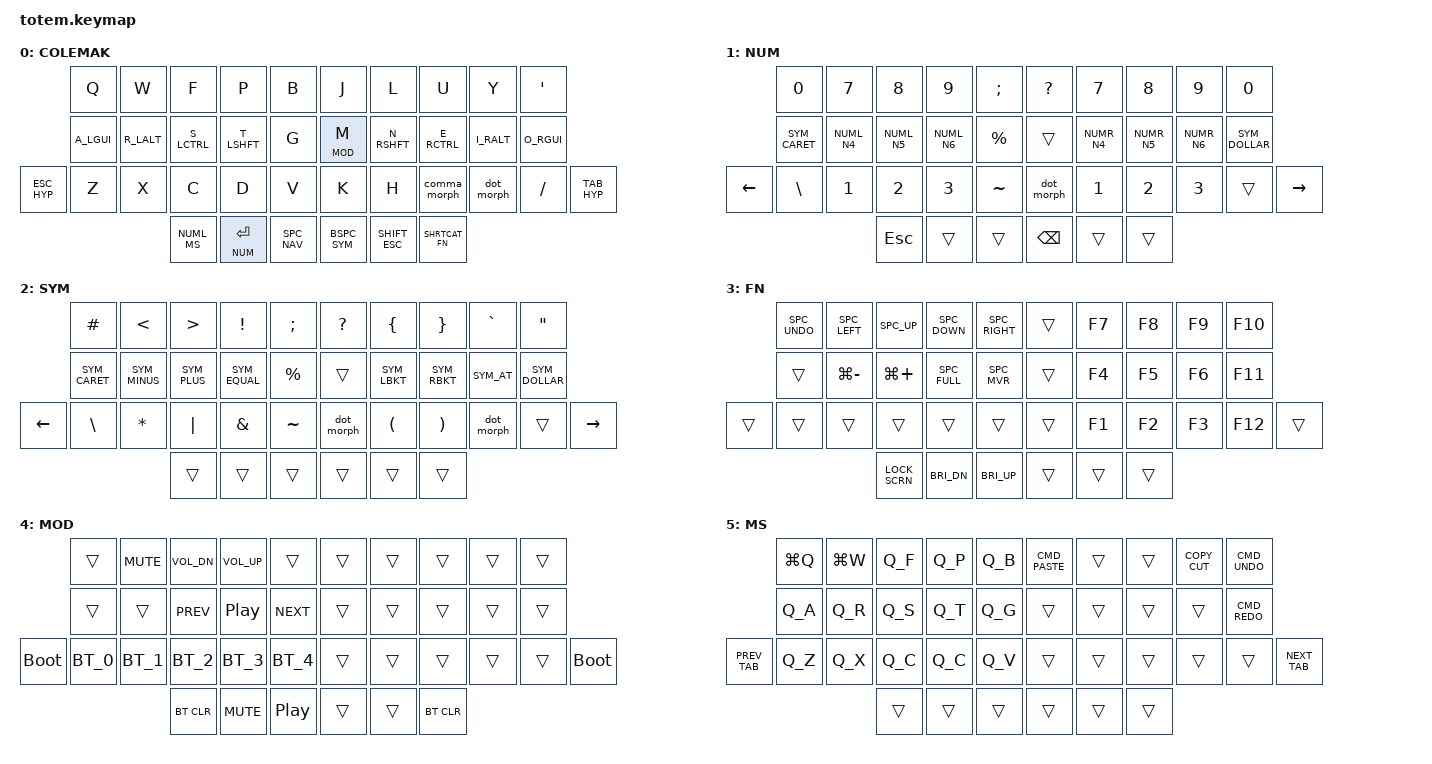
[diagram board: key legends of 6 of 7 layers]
//
//                                                        ▀▀▀▀▀     ▀▀▀▀▀          ▀▀█▀▀
//                                                        ▄▀▀▀▄  ▄  ▄▀▀▀▄  ▄  ▄▀▀▀▄  █  ▄▀▀▀▄
//                                                        █   █  █  █   █  █  █   █  █  █   █
//                                                         ▀▀▀   █   ▀▀▀   █   ▀▀▀   ▀   ▀▀▀
//                                                               █      ▄▄▄█▄▄▄    █   █
//                                                               ▀      █  █  █     █▄█
//                                                             ▀▀▀▀▀    █  █  █      ▀
//                                                                      ▀  ▀  ▀
//
// ▄▄▄▄▄▄▄▄▄▄▄▄▄▄▄▄▄▄▄▄▄▄▄▄▄▄▄▄▄▄▄▄▄▄▄▄▄▄▄▄▄▄▄▄▄▄▄▄▄▄▄▄▄▄▄▄▄▄▄▄▄▄▄▄▄▄▄▄▄▄▄▄▄▄▄▄▄▄▄▄▄▄▄▄▄▄▄▄▄▄▄▄▄▄▄▄▄▄▄▄▄▄▄▄▄▄▄▄▄▄▄▄▄▄▄▄▄▄▄▄▄▄▄▄▄▄▄▄▄▄▄▄▄▄▄▄▄▄▄▄▄▄▄▄▄▄▄▄▄


#include <behaviors.dtsi>
#include <behaviors/num_word.dtsi>
#include <dt-bindings/zmk/keys.h>
#include <dt-bindings/zmk/bt.h>
#include <dt-bindings/zmk/outputs.h>
#include "zmk-helpers/helper.h"

#include "totem_keypos.h"

#include "mouse.h"

#define ___ &trans

#define DEF 0 // Default colemak layer
#define NUM 1
#define SYM 2
#define FN 3
#define MOD 4
#define MS 5
#define NAV 6

/* Global settings */
#include "general.h"

/* Home row mods */
#include "homerow_mods.h"

/* Macros and shortcuts */
#include "custom_behaviors.h"

#include "combos.h"

/ {
        keymap {
                compatible = "zmk,keymap";
// ▄▄▄▄▄▄▄▄▄▄▄▄▄▄▄▄▄▄▄▄▄▄▄▄▄▄▄▄▄▄▄▄▄▄▄▄▄▄▄▄▄▄▄▄▄▄▄▄▄▄▄▄▄▄▄▄▄▄▄▄▄▄▄▄▄▄▄▄▄▄▄▄▄▄▄▄▄▄▄▄▄▄▄▄▄▄▄▄▄▄▄▄▄▄▄▄▄▄▄▄▄▄▄▄▄▄▄▄▄▄▄▄▄▄▄▄▄▄▄▄▄▄▄▄▄▄▄▄▄▄▄▄▄▄▄▄▄▄▄▄▄▄▄▄▄▄▄▄▄▄▄▄▄▄▄▄▄▄▄▄▄▄▄▄▄▄▄▄▄▄▄▄▄

                colemak_layer {
  // ┏━━━━━━━━━━━━━━━━━━━━━━━━━━━━━━━━━━━━━━━━━━━━━┓
  label= "COLEMAK"                                 ;
  // ┗━━━━━━━━━━━━━━━━━━━━━━━━━━━━━━━━━━━━━━━━━━━━━┛
  bindings = <
  //               ┏━━━━━━━━━━━━━┳━━━━━━━━━━━━━┳━━━━━━━━━━━━━┳━━━━━━━━━━━━━┳━━━━━━━━━━━━━┓   ┏━━━━━━━━━━━━━┳━━━━━━━━━━━━━┳━━━━━━━━━━━━━┳━━━━━━━━━━━━━┳━━━━━━━━━━━━━┓
                    &kp Q         &kp W         &kp F         &kp P         &kp B             &kp J         &kp L         &kp U         &kp Y         &kp SQT
  //               ┣━━━━━━━━━━━━━╋━━━━━━━━━━━━━╋━━━━━━━━━━━━━╋━━━━━━━━━━━━━╋━━━━━━━━━━━━━┫   ┣━━━━━━━━━━━━━╋━━━━━━━━━━━━━╋━━━━━━━━━━━━━╋━━━━━━━━━━━━━╋━━━━━━━━━━━━━┫
                    A_LGUI        R_LALT        S_LCTRL       T_LSHFT       &kp G             &lt MOD M     N_RSHFT       E_RCTRL       I_RALT        O_RGUI
  // ┏━━━━━━━━━━━━━╋━━━━━━━━━━━━━╋━━━━━━━━━━━━━╋━━━━━━━━━━━━━╋━━━━━━━━━━━━━╋━━━━━━━━━━━━━┫   ┣━━━━━━━━━━━━━╋━━━━━━━━━━━━━╋━━━━━━━━━━━━━╋━━━━━━━━━━━━━╋━━━━━━━━━━━━━╋━━━━━━━━━━━━━┓
      ESC_HYP       &kp Z         &kp X         &kp C         &kp D         &kp V             &kp K         &kp H         &comma_morph  &dot_morph    &kp FSLH      TAB_HYP
  // ┗━━━━━━━━━━━━━┻━━━━━━━━━━━━━┻━━━━━━━━━━━━━╋━━━━━━━━━━━━━╋━━━━━━━━━━━━━╋━━━━━━━━━━━━━┫   ┣━━━━━━━━━━━━━╋━━━━━━━━━━━━━╋━━━━━━━━━━━━━╋━━━━━━━━━━━━━┻━━━━━━━━━━━━━┻━━━━━━━━━━━━━┛
                                                NUML_MS      &lt NUM ENTER  SPC_NAV           BSPC_SYM      SHIFT_ESC     SHRTCAT_FN
  //                                           ┗━━━━━━━━━━━━━┻━━━━━━━━━━━━━┻━━━━━━━━━━━━━┛   ┗━━━━━━━━━━━━━┻━━━━━━━━━━━━━┻━━━━━━━━━━━━━┛
                        >;
                };

// ▄▄▄▄▄▄▄▄▄▄▄▄▄▄▄▄▄▄▄▄▄▄▄▄▄▄▄▄▄▄▄▄▄▄▄▄▄▄▄▄▄▄▄▄▄▄▄▄▄▄▄▄▄▄▄▄▄▄▄▄▄▄▄▄▄▄▄▄▄▄▄▄▄▄▄▄▄▄▄▄▄▄▄▄▄▄▄▄▄▄▄▄▄▄▄▄▄▄▄▄▄▄▄▄▄▄▄▄▄▄▄▄▄▄▄▄▄▄▄▄▄▄▄▄▄▄▄▄▄▄▄▄▄▄▄▄▄▄▄▄▄▄▄▄▄▄▄▄▄▄▄▄▄▄▄▄▄▄▄▄▄▄▄▄▄▄▄▄▄▄▄▄▄

                num_layer {
  // ┏━━━━━━━━━━━━━━━━━━━━━━━━━━━━━━━━━━━━━━━━━━━━━┓
  label= "NUM"                                     ;
  // ┗━━━━━━━━━━━━━━━━━━━━━━━━━━━━━━━━━━━━━━━━━━━━━┛
  bindings = <
  //               ┏━━━━━━━━━━━━━┳━━━━━━━━━━━━━┳━━━━━━━━━━━━━┳━━━━━━━━━━━━━┳━━━━━━━━━━━━━┓   ┏━━━━━━━━━━━━━┳━━━━━━━━━━━━━┳━━━━━━━━━━━━━┳━━━━━━━━━━━━━┳━━━━━━━━━━━━━┓
                    &kp N0        &kp N7        &kp N8        &kp N9        &kp SEMI          &kp QMARK      &kp N7        &kp N8        &kp N9        &kp N0
  //               ┣━━━━━━━━━━━━━╋━━━━━━━━━━━━━╋━━━━━━━━━━━━━╋━━━━━━━━━━━━━╋━━━━━━━━━━━━━┫   ┣━━━━━━━━━━━━━╋━━━━━━━━━━━━━╋━━━━━━━━━━━━━╋━━━━━━━━━━━━━╋━━━━━━━━━━━━━┫
                    SYM_CARET     NUML_N4       NUML_N5       NUML_N6       &kp PRCNT         ___            NUMR_N4       NUMR_N5       NUMR_N6       SYM_DOLLAR
  // ┏━━━━━━━━━━━━━╋━━━━━━━━━━━━━╋━━━━━━━━━━━━━╋━━━━━━━━━━━━━╋━━━━━━━━━━━━━╋━━━━━━━━━━━━━┫   ┣━━━━━━━━━━━━━╋━━━━━━━━━━━━━╋━━━━━━━━━━━━━╋━━━━━━━━━━━━━╋━━━━━━━━━━━━━╋━━━━━━━━━━━━━┓
      &kp LEFT      &kp BSLH      &kp N1        &kp N2        &kp N3        &kp TILDE         &dot_morph     &kp N1        &kp N2        &kp N3        ___          &kp RIGHT
  // ┗━━━━━━━━━━━━━┻━━━━━━━━━━━━━┻━━━━━━━━━━━━━╋━━━━━━━━━━━━━╋━━━━━━━━━━━━━╋━━━━━━━━━━━━━┫   ┣━━━━━━━━━━━━━╋━━━━━━━━━━━━━╋━━━━━━━━━━━━━╋━━━━━━━━━━━━━┻━━━━━━━━━━━━━┻━━━━━━━━━━━━━┛
                                                &kp ESC       ___           ___               &kp BSPC       ___           ___
  //                                           ┗━━━━━━━━━━━━━┻━━━━━━^━━━━━━┻━━━━━━━━━━━━━┛   ┗━━━━━━━━━━━━━┻━━━━━━━━━━━━━┻━━━━━━━━━━━━━┛
                        >;
                };
// ▄▄▄▄▄▄▄▄▄▄▄▄▄▄▄▄▄▄▄▄▄▄▄▄▄▄▄▄▄▄▄▄▄▄▄▄▄▄▄▄▄▄▄▄▄▄▄▄▄▄▄▄▄▄▄▄▄▄▄▄▄▄▄▄▄▄▄▄▄▄▄▄▄▄▄▄▄▄▄▄▄▄▄▄▄▄▄▄▄▄▄▄▄▄▄▄▄▄▄▄▄▄▄▄▄▄▄▄▄▄▄▄▄▄▄▄▄▄▄▄▄▄▄▄▄▄▄▄▄▄▄▄▄▄▄▄▄▄▄▄▄▄▄▄▄▄▄▄▄▄▄▄▄▄▄▄▄▄▄▄▄▄▄▄▄▄▄▄▄▄▄▄▄

                sym_layer {
  // ┏━━━━━━━━━━━━━━━━━━━━━━━━━━━━━━━━━━━━━━━━━━━━━┓
  label= "SYM"                                     ;
  // ┗━━━━━━━━━━━━━━━━━━━━━━━━━━━━━━━━━━━━━━━━━━━━━┛
  bindings = <
  //               ┏━━━━━━━━━━━━━┳━━━━━━━━━━━━━┳━━━━━━━━━━━━━┳━━━━━━━━━━━━━┳━━━━━━━━━━━━━┓   ┏━━━━━━━━━━━━━┳━━━━━━━━━━━━━┳━━━━━━━━━━━━━┳━━━━━━━━━━━━━┳━━━━━━━━━━━━━┓
                    &kp HASH      &kp LT        &kp GT        &kp EXCL      &kp SEMI          &kp QMARK     &kp LBRC      &kp RBRC      &kp GRAVE     &kp DQT
  //               ┣━━━━━━━━━━━━━╋━━━━━━━━━━━━━╋━━━━━━━━━━━━━╋━━━━━━━━━━━━━╋━━━━━━━━━━━━━┫   ┣━━━━━━━━━━━━━╋━━━━━━━━━━━━━╋━━━━━━━━━━━━━╋━━━━━━━━━━━━━╋━━━━━━━━━━━━━┫
                    SYM_CARET     SYM_MINUS     SYM_PLUS      SYM_EQUAL     &kp PRCNT         ___           SYM_LBKT      SYM_RBKT      SYM_AT        SYM_DOLLAR
  // ┏━━━━━━━━━━━━━╋━━━━━━━━━━━━━╋━━━━━━━━━━━━━╋━━━━━━━━━━━━━╋━━━━━━━━━━━━━╋━━━━━━━━━━━━━┫   ┣━━━━━━━━━━━━━╋━━━━━━━━━━━━━╋━━━━━━━━━━━━━╋━━━━━━━━━━━━━╋━━━━━━━━━━━━━╋━━━━━━━━━━━━━┓
      &kp LEFT      &kp BSLH      &kp STAR      &kp PIPE      &kp AMPS      &kp TILDE         &dot_morph    &kp LPAR      &kp RPAR      &dot_morph    ___           &kp RIGHT
  // ┗━━━━━━━━━━━━━┻━━━━━━━━━━━━━┻━━━━━━━━━━━━━╋━━━━━━━━━━━━━╋━━━━━━━━━━━━━╋━━━━━━━━━━━━━┫   ┣━━━━━━━━━━━━━╋━━━━━━━━━━━━━╋━━━━━━━━━━━━━╋━━━━━━━━━━━━━┻━━━━━━━━━━━━━┻━━━━━━━━━━━━━┛
                                                ___           ___           ___               ___           ___           ___
  //                                           ┗━━━━━━━━━━━━━┻━━━━━━━━━━━━━┻━━━━━━━━━━━━━┛   ┗━━━━━━^━━━━━━┻━━━━━━━━━━━━━┻━━━━━━━━━━━━━┛
                        >;
                };
// ▄▄▄▄▄▄▄▄▄▄▄▄▄▄▄▄▄▄▄▄▄▄▄▄▄▄▄▄▄▄▄▄▄▄▄▄▄▄▄▄▄▄▄▄▄▄▄▄▄▄▄▄▄▄▄▄▄▄▄▄▄▄▄▄▄▄▄▄▄▄▄▄▄▄▄▄▄▄▄▄▄▄▄▄▄▄▄▄▄▄▄▄▄▄▄▄▄▄▄▄▄▄▄▄▄▄▄▄▄▄▄▄▄▄▄▄▄▄▄▄▄▄▄▄▄▄▄▄▄▄▄▄▄▄▄▄▄▄▄▄▄▄▄▄▄▄▄▄▄▄▄▄▄▄▄▄▄▄▄▄▄▄▄▄▄▄▄▄▄▄▄▄▄

                fn_layer {
  // ┏━━━━━━━━━━━━━━━━━━━━━━━━━━━━━━━━━━━━━━━━━━━━━┓
  label= "FN"                                      ;
  // ┗━━━━━━━━━━━━━━━━━━━━━━━━━━━━━━━━━━━━━━━━━━━━━┛
  bindings = <
  //               ┏━━━━━━━━━━━━━┳━━━━━━━━━━━━━┳━━━━━━━━━━━━━┳━━━━━━━━━━━━━┳━━━━━━━━━━━━━┓   ┏━━━━━━━━━━━━━┳━━━━━━━━━━━━━┳━━━━━━━━━━━━━┳━━━━━━━━━━━━━┳━━━━━━━━━━━━━┓
                    SPC_UNDO      SPC_LEFT      SPC_UP        SPC_DOWN      SPC_RIGHT         ___           &kp F7        &kp F8        &kp F9        &kp F10
  //               ┣━━━━━━━━━━━━━╋━━━━━━━━━━━━━╋━━━━━━━━━━━━━╋━━━━━━━━━━━━━╋━━━━━━━━━━━━━┫   ┣━━━━━━━━━━━━━╋━━━━━━━━━━━━━╋━━━━━━━━━━━━━╋━━━━━━━━━━━━━╋━━━━━━━━━━━━━┫
                    ___          &kp LG(MINUS)  &kp LG(PLUS)  SPC_FULL      SPC_MVR           ___           &kp F4        &kp F5        &kp F6        &kp F11
  // ┏━━━━━━━━━━━━━╋━━━━━━━━━━━━━╋━━━━━━━━━━━━━╋━━━━━━━━━━━━━╋━━━━━━━━━━━━━╋━━━━━━━━━━━━━┫   ┣━━━━━━━━━━━━━╋━━━━━━━━━━━━━╋━━━━━━━━━━━━━╋━━━━━━━━━━━━━╋━━━━━━━━━━━━━╋━━━━━━━━━━━━━┓
      ___           ___           ___           ___           ___           ___               ___           &kp F1        &kp F2        &kp F3        &kp F12       ___
  // ┗━━━━━━━━━━━━━┻━━━━━━━━━━━━━┻━━━━━━━━━━━━━╋━━━━━━━━━━━━━╋━━━━━━━━━━━━━╋━━━━━━━━━━━━━┫   ┣━━━━━━━━━━━━━╋━━━━━━━━━━━━━╋━━━━━━━━━━━━━╋━━━━━━━━━━━━━┻━━━━━━━━━━━━━┻━━━━━━━━━━━━━┛
                                                LOCK_SCRN     &kp C_BRI_DN  &kp C_BRI_UP      ___           ___           ___
  //                                           ┗━━━━━━━━━━━━━┻━━━━━━━━━━━━━┻━━━━━━━━━━━━━┛   ┗━━━━━━━━━━━━━┻━━━━━━━━━━━━━┻━━━━━━^━━━━━━┛
                        >;
                };
// ▄▄▄▄▄▄▄▄▄▄▄▄▄▄▄▄▄▄▄▄▄▄▄▄▄▄▄▄▄▄▄▄▄▄▄▄▄▄▄▄▄▄▄▄▄▄▄▄▄▄▄▄▄▄▄▄▄▄▄▄▄▄▄▄▄▄▄▄▄▄▄▄▄▄▄▄▄▄▄▄▄▄▄▄▄▄▄▄▄▄▄▄▄▄▄▄▄▄▄▄▄▄▄▄▄▄▄▄▄▄▄▄▄▄▄▄▄▄▄▄▄▄▄▄▄▄▄▄▄▄▄▄▄▄▄▄▄▄▄▄▄▄▄▄▄▄▄▄▄▄▄▄▄▄▄▄▄▄▄▄▄▄▄▄▄▄▄▄▄▄▄▄▄

                mod_layer {
  // ┏━━━━━━━━━━━━━━━━━━━━━━━━━━━━━━━━━━━━━━━━━━━━━┓
  label= "MOD"                                     ;
  // ┗━━━━━━━━━━━━━━━━━━━━━━━━━━━━━━━━━━━━━━━━━━━━━┛
  bindings = <
  //               ┏━━━━━━━━━━━━━┳━━━━━━━━━━━━━┳━━━━━━━━━━━━━┳━━━━━━━━━━━━━┳━━━━━━━━━━━━━┓   ┏━━━━━━━━━━━━━┳━━━━━━━━━━━━━┳━━━━━━━━━━━━━┳━━━━━━━━━━━━━┳━━━━━━━━━━━━━┓
                    ___           &kp C_MUTE    &kp C_VOL_DN  &kp C_VOL_UP  ___               ___           ___           ___           ___           ___
  //               ┣━━━━━━━━━━━━━╋━━━━━━━━━━━━━╋━━━━━━━━━━━━━╋━━━━━━━━━━━━━╋━━━━━━━━━━━━━┫   ┣━━━━━━━━━━━━━╋━━━━━━━━━━━━━╋━━━━━━━━━━━━━╋━━━━━━━━━━━━━╋━━━━━━━━━━━━━┫
                    ___           ___           &kp C_PREV    &kp C_PP      &kp C_NEXT        ___           ___           ___           ___           ___
  // ┏━━━━━━━━━━━━━╋━━━━━━━━━━━━━╋━━━━━━━━━━━━━╋━━━━━━━━━━━━━╋━━━━━━━━━━━━━╋━━━━━━━━━━━━━┫   ┣━━━━━━^━━━━━━╋━━━━━━━━━━━━━╋━━━━━━━━━━━━━╋━━━━━━━━━━━━━╋━━━━━━━━━━━━━╋━━━━━━━━━━━━━┓
      &bootloader   BT_0          BT_1          BT_2          BT_3          BT_4              ___           ___           ___           ___           ___           &bootloader
  // ┗━━━━━━━━━━━━━┻━━━━━━━━━━━━━┻━━━━━━━━━━━━━╋━━━━━━━━━━━━━╋━━━━━━━━━━━━━╋━━━━━━━━━━━━━┫   ┣━━━━━━━━━━━━━╋━━━━━━━━━━━━━╋━━━━━━━━━━━━━╋━━━━━━━━━━━━━┻━━━━━━━━━━━━━┻━━━━━━━━━━━━━┛
                                                &bt BT_CLR    &kp C_MUTE    &kp C_PP          ___           ___           &bt BT_CLR
  //                                           ┗━━━━━━━━━━━━━┻━━━━━━━━━━━━━┻━━━━━━━━━━━━━┛   ┗━━━━━━━━━━━━━┻━━━━━━━━━━━━━┻━━━━━━━━━━━━━┛
                        >;
                };
// ▄▄▄▄▄▄▄▄▄▄▄▄▄▄▄▄▄▄▄▄▄▄▄▄▄▄▄▄▄▄▄▄▄▄▄▄▄▄▄▄▄▄▄▄▄▄▄▄▄▄▄▄▄▄▄▄▄▄▄▄▄▄▄▄▄▄▄▄▄▄▄▄▄▄▄▄▄▄▄▄▄▄▄▄▄▄▄▄▄▄▄▄▄▄▄▄▄▄▄▄▄▄▄▄▄▄▄▄▄▄▄▄▄▄▄▄▄▄▄▄▄▄▄▄▄▄▄▄▄▄▄▄▄▄▄▄▄▄▄▄▄▄▄▄▄▄▄▄▄▄▄▄▄▄▄▄▄▄▄▄▄▄▄▄▄▄▄▄▄▄▄▄▄

                mouse_layer {
  // ┏━━━━━━━━━━━━━━━━━━━━━━━━━━━━━━━━━━━━━━━━━━━━━┓
  label= "MS"                                      ;
  // ┗━━━━━━━━━━━━━━━━━━━━━━━━━━━━━━━━━━━━━━━━━━━━━┛
  bindings = <
  //               ┏━━━━━━━━━━━━━┳━━━━━━━━━━━━━┳━━━━━━━━━━━━━┳━━━━━━━━━━━━━┳━━━━━━━━━━━━━┓   ┏━━━━━━━━━━━━━┳━━━━━━━━━━━━━┳━━━━━━━━━━━━━┳━━━━━━━━━━━━━┳━━━━━━━━━━━━━┓
                    &kp LG(Q)     &kp LG(W)     Q_F           Q_P           Q_B               CMD_PASTE     ___           ___           COPY_CUT      CMD_UNDO
  //               ┣━━━━━━━━━━━━━╋━━━━━━━━━━━━━╋━━━━━━━━━━━━━╋━━━━━━━━━━━━━╋━━━━━━━━━━━━━┫   ┣━━━━━━━━━━━━━╋━━━━━━━━━━━━━╋━━━━━━━━━━━━━╋━━━━━━━━━━━━━╋━━━━━━━━━━━━━┫
                    Q_A           Q_R           Q_S           Q_T           Q_G               ___           ___           ___           ___           CMD_REDO
  // ┏━━━━━━━━━━━━━╋━━━━━━━━━━━━━╋━━━━━━━━━━━━━╋━━━━━━━━━━━━━╋━━━━━━━━━━━━━╋━━━━━━━━━━━━━┫   ┣━━━━━━━━━━━━━╋━━━━━━━━━━━━━╋━━━━━━━━━━━━━╋━━━━━━━━━━━━━╋━━━━━━━━━━━━━╋━━━━━━━━━━━━━┓
      PREV_TAB      Q_Z           Q_X           Q_C           Q_C           Q_V               ___           ___           ___           ___           ___           NEXT_TAB
  // ┗━━━━━━━━━━━━━┻━━━━━━━━━━━━━┻━━━━━━━━━━━━━╋━━━━━━━━━━━━━╋━━━━━━━━━━━━━╋━━━━━━━━━━━━━┫   ┣━━━━━━━━━━━━━╋━━━━━━━━━━━━━╋━━━━━━━━━━━━━╋━━━━━━━━━━━━━┻━━━━━━━━━━━━━┻━━━━━━━━━━━━━┛
                                                ___           ___           ___               ___           ___           ___
  //                                           ┗━━━━━━━━━━━━━┻━━━━━━━━━━━━━┻━━━━━━^━━━━━━┛   ┗━━━━━━━━━━━━━┻━━━━━━━━━━━━━┻━━━━━━━━━━━━━┛
                        >;
                };
// ▄▄▄▄▄▄▄▄▄▄▄▄▄▄▄▄▄▄▄▄▄▄▄▄▄▄▄▄▄▄▄▄▄▄▄▄▄▄▄▄▄▄▄▄▄▄▄▄▄▄▄▄▄▄▄▄▄▄▄▄▄▄▄▄▄▄▄▄▄▄▄▄▄▄▄▄▄▄▄▄▄▄▄▄▄▄▄▄▄▄▄▄▄▄▄▄▄▄▄▄▄▄▄▄▄▄▄▄▄▄▄▄▄▄▄▄▄▄▄▄▄▄▄▄▄▄▄▄▄▄▄▄▄▄▄▄▄▄▄▄▄▄▄▄▄▄▄▄▄▄▄▄▄▄▄▄▄▄▄▄▄▄▄▄▄▄▄▄▄▄▄▄▄

                nav_layer {
  // ┏━━━━━━━━━━━━━━━━━━━━━━━━━━━━━━━━━━━━━━━━━━━━━┓
  label= "NAV"                                     ;
  // ┗━━━━━━━━━━━━━━━━━━━━━━━━━━━━━━━━━━━━━━━━━━━━━┛
  bindings = <
  //               ┏━━━━━━━━━━━━━┳━━━━━━━━━━━━━┳━━━━━━━━━━━━━┳━━━━━━━━━━━━━┳━━━━━━━━━━━━━┓   ┏━━━━━━━━━━━━━┳━━━━━━━━━━━━━┳━━━━━━━━━━━━━┳━━━━━━━━━━━━━┳━━━━━━━━━━━━━┓
                    PREV_WINDOW   NEXT_WINDOW   PREV_TAB      NEXT_TAB      ___               CMD_PASTE     &kp PG_DN     &kp PG_UP     COPY_CUT      CMD_UNDO
  //               ┣━━━━━━━━━━━━━╋━━━━━━━━━━━━━╋━━━━━━━━━━━━━╋━━━━━━━━━━━━━╋━━━━━━━━━━━━━┫   ┣━━━━━━━━━━━━━╋━━━━━━━━━━━━━╋━━━━━━━━━━━━━╋━━━━━━━━━━━━━╋━━━━━━━━━━━━━┫
                    SYM_CARET     ___           ___           ___           ___               &kp LEFT      &kp DOWN      &kp UP        &kp RIGHT     SYM_DOLLAR
  // ┏━━━━━━━━━━━━━╋━━━━━━━━━━━━━╋━━━━━━━━━━━━━╋━━━━━━━━━━━━━╋━━━━━━━━━━━━━╋━━━━━━━━━━━━━┫   ┣━━━━━━━━━━━━━╋━━━━━━━━━━━━━╋━━━━━━━━━━━━━╋━━━━━━━━━━━━━╋━━━━━━━━━━━━━╋━━━━━━━━━━━━━┓
      TAB_HYP       &kp BSLH      &kp BSPC      SWAP_PREV     &swapper      CMD_PASTE         ___           ___           ___           ___           ___           ESC_HYP
  // ┗━━━━━━━━━━━━━┻━━━━━━━━━━━━━┻━━━━━━━━━━━━━╋━━━━━━━━━━━━━╋━━━━━━━━━━━━━╋━━━━━━━━━━━━━┫   ┣━━━━━━━━━━━━━╋━━━━━━━━━━━━━╋━━━━━━━━━━━━━╋━━━━━━━━━━━━━┻━━━━━━━━━━━━━┻━━━━━━━━━━━━━┛
                                                ___           ___           ___               &bs_del       ___           ___
  //                                           ┗━━━━━━━━━━━━━┻━━━━━━━━━━━━━┻━━━━━━^━━━━━━┛   ┗━━━━━━━━━━━━━┻━━━━━━━━━━━━━┻━━━━━━━━━━━━━┛
                        >;
                };

        };
};
